# MMCHS1 register map
Vendor: Texas Instruments
Peripheral module from a debugger description file (folder omap4430).
Registers are 32-bit, access per field, reset 0x0 unless marked. A register's access mark holds for its fields unless they carry their own. Offsets are as the file gives them; lines under a group give offsets from that group; [hi:lo] are bit positions; {n}, {i} and the like mark numbered series; 'fields as' and 'values as' point back to an identical list; <NAME> marks a mode.

## MMCHS1 (part 1 of 2)
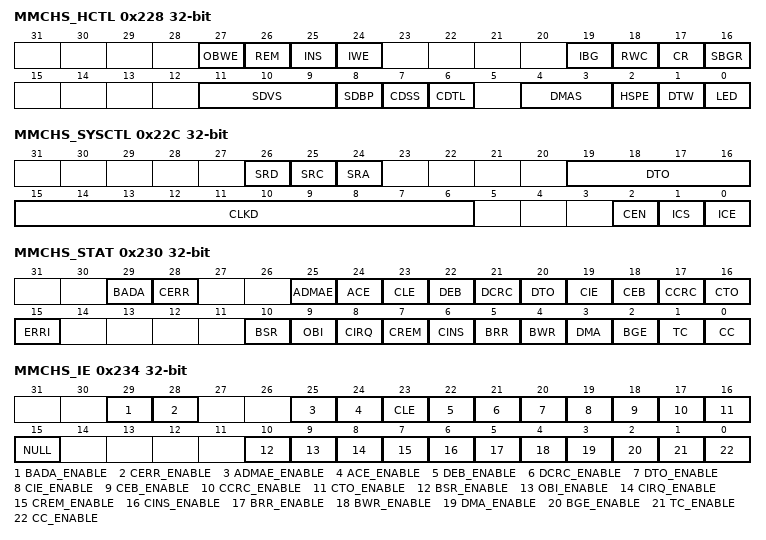
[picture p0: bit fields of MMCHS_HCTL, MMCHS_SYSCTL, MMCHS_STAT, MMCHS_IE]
0x228 MMCHS_HCTL — Control register This register defines the host controls to set power, wakeup and transfer parameters. [31:24] = Wakeup control [23:16] = Block gap control [15:8] = Power control [7:0] = Host control
  [27] OBWE rw — Wakeup event enable for 'Out-of-Band' Interrupt. This bit enables wakeup events for 'Out-of-Band' assertion. Wakeup is generated if the wakeup feature is enabled (MMCHS_SYSCONFIG[2] ENAWAKEUP). The write to this register is ignored when MMCHS_CON[14] OBIE is not set.
    0=Disable wakeup on 'Out-of-Band' Interrupt; 1=Enable wakeup on 'Out-of-Band' Interrupt
  [26] REM rw — Wakeup event enable on SD card removal This bit enables wakeup events for card removal assertion. Wakeup is generated if the wakeup feature is enabled (MMCHS_SYSCONFIG[2] ENAWAKEUP).
    0=Disable wakeup on card removal; 1=Enable wakeup on card removal
  [25] INS rw — Wakeup event enable on SD card insertion This bit enables wakeup events for card insertion assertion. Wakeup is generated if the wakeup feature is enabled (MMCHS_SYSCONFIG[2] ENAWAKEUP).
    0=Disable wakeup on card insertion; 1=Enable wakeup on card insertion
  [24] IWE rw — Wakeup event enable on SD card interrupt This bit enables wakeup events for card interrupt assertion. Wakeup is generated if the wakeup feature is enabled (MMCHS_SYSCONFIG[2] ENAWAKEUP).
    0=Disable wakeup on card interrupt; 1=Enable wakeup on card interrupt
  [19] IBG rw — Interrupt block at gap This bit is valid only in 4-bit mode of SDIO card to enable interrupt detection in the interrupt cycle at block gap for a multiple block transfer. For MMC cards and for SD card this bit should be set to 0.
    0=Disable interrupt detection at the block gap in 4-bit mode; 1=Enable interrupt detection at the block gap in 4-bit mode
  [18] RWC rw — Read wait control The read wait function is optional only for SDIO cards. If the card supports read wait, this bit must be enabled, then requesting a stop at block gap (MMCHS_HCTL[16] SBGR) generates a read wait period after the current end of block. Be careful, if read wait is not supported it may cause a conflict on DAT line.
    0=Disable Read Wait Control. Suspend/Resume cannot be supported.; 1=Enable Read Wait Control
  [17] CR rw — Continue request This bit is used to restart a transaction that was stopped by requesting a stop at block gap (MMCHS_HCTL[16] SBGR). Set this bit to 1 restarts the transfer. The bit is automatically set to 0 by the host controller when transfer has restarted i.e DAT line is active (MMCHS_PSTATE[2] DLA) or transferring data (MMCHS_PSTATE[8] WTA). The Stop at block gap request must be disabled (MMCHS_HCTL[16] SBGR = 0) before setting this bit.
    0=No affect; 1=transfer restart
  [16] SBGR rw — Stop at block gap request This bit is used to stop executing a transaction at the next block gap. The transfer can restart with a continue request (MMCHS_HCTL[17] CR) or during a suspend/resume sequence. In case of read transfer, the card must support read wait control. In case of write transfer, the host driver shall set this bit after all block data written. Until the transfer completion (MMCHS_STAT[1] TC set to 1), the host driver shall leave this bit set to 1. If this bit is set, the local host shall not write to the data register (MMCHS_DATA).
    0=Transfer mode; 1=Stop at block gap
  [11:9] SDVS rw — SD bus voltage select All cards. The host driver should set to these bits to select the voltage level for the card according to the voltage supported by the system (MMCHS_CAPA[26:24]) before starting a transfer.
    5=1.8V (Typical); 6=3.0V (Typical); 7=3.3V (Typical)
  [8] SDBP rw — SD bus power Before setting this bit, the host driver shall select the SD bus voltage (MMCHS_HCTL[11:9] SDVS). If the host controller detects the No card state, this bit is automatically set to 0. If the module is power off, a write in the command register (MMCHS_CMD) will not start the transfer. A write to this bit has no effect if the selected SD bus voltage is not supported according to capability register (MMCHS_CAPA[26:24]).
    0=Power off; 1=Power on
  [7] CDSS rw — Card Detect Signal Selection This bit selects source for the card detection.When the source for the card detection is switched, the interrupt should be disabled during the switching period by clearing the Interrupt Status/Signal Enable register in order to mask unexpected interrupt being caused by the glitch. The Interrupt Status/Signal Enable should be disabled during over the period of debouncing.
    0=SDCD# is selected (for normal use); 1=The Card Detect Test Level is selected (for test purpose)
  [6] CDTL rw — Card Detect Test Level: This bit is enabled while the Card Detect Signal Selection is set to 1 and it indicates card inserted or not.
    0=No Card; 1=Card Inserted
  [4:3] DMAS rw — DMA Select Mode: One of supported DMA modes can be selected. The host driver shall check support of DMA modes by referring the Capabilities register. Use of selected DMA is determined by DMA Enable of the Transfer Mode register. This register is only meaningful when MMCHS_HL_HWINFO[0] MADMA_EN is set to 1. When MMCHS_HL_HWINFO[0] MADMA_EN is set to 0 the bit field is read only and returned value is 0.
    2=32-bit Address ADMA2 is selected
  [2] HSPE rw — High Speed Enable: Before setting this bit, the Host Driver shall check the High Speed Support in the Capabilities register. If this bit is set to 0 (default), the Host Controller outputs CMD line and DAT lines at the falling edge of the SD Clock. If this bit is set to 1, the Host Controller outputs CMD line and DAT lines at the rising edge of the SD Clock.This bit shall not be set when dual data rate mode is activated in MMCHS_CON[19] DDR.
    0=Normal speed mode; 1=High speed mode
  [1] DTW rw — Data transfer width For MMC card, this bit must be set following a valid SWITCH command (CMD6) with the correct value and extend CSD index written in the argument. Prior to this command, the MMC card configuration register (CSD and EXT_CSD) must be verified for compliance with MMC standard specification 4.x (see section 3.6). This register has no effect when the MMC 8-bit mode is selected (register MMCHS_CON[5] DW8 set to1 ), For SD/SDIO cards, this bit must be set following a valid SET_BUS_WIDTH command (ACMD6) with the value written in bit 1 of the argument. Prior to this command, the SD card configuration register (SCR) must be verified for the supported bus width by the SD card.
    0=1-bit Data width (DAT[0] used); 1=4-bit Data width (DAT[3:0] used)
  [0] LED ro — Reserved bit. LED control feature is not supported This bit is initialized to zero, and writes to it are ignored.
0x22C MMCHS_SYSCTL — SD system control register This register defines the system controls to set software resets, clock frequency management and data timeout. [31:24] = Software resets [23:16] = Timeout control [15:0] = Clock control
  [26] SRD rw — Software reset for DAT line. This bit is set to 1 for reset and released to 0 when completed. For more information about SRD bit manipulation, see , . DAT finite state machine in both clock domain are also reset. The following registers are cleared by MMCHS_SYSCTL[26] SRD: - MMCHS_DATA - MMCHS_PSTATE[11] BRE, MMCHS_PSTATE[10] BWE, MMCHS_PSTATE[9] RTA, MMCHS_PSTATE[8] WTA, MMCHS_PSTATE[2] DLA, MMCHS_PSTATE[1] DATI - MMCHS_HCTL: SBGR and CR - MMCHS_STAT: MMCHS_STAT[5] BRR, MMCHS_STAT[4] BWR, MMCHS_STAT[2] BGE and MMCHS_STAT[1] TC Interconnect and MMC buffer data management is reinitialized.
    0=Reset completed; 1=Software reset for DAT line
  [25] SRC rw — Software reset for CMD line For more information about SRC bit manipulation, see , . This bit is set to 1 for reset and released to 0 when completed. CMD finite state-machine in both clock domain are also reset. The following registers are cleared by MMCHS_SYSCTL[25] SRC: - MMCHS_PSTATE[0] CMDI - MMCHS_STAT[0] CC Interconnect and MMC command status management is reinitialized.
    0=Reset completed; 1=Software reset for CMD line
  [24] SRA rw — Software reset for all This bit is set to 1 for reset, and released to 0 when completed. This reset affects the entire host controller except for the card detection circuit and capabilities registers.
    0=Reset completed; 1=Software reset for all the design
  [19:16] DTO rw — Data timeout counter value and busy timeout. This value determines the interval by which DAT lines timeouts are detected. The host driver needs to set this bit field based on - the maximum read access time (NAC) (Refer to the SD Specification Part1 Physical Layer), - the data read access time values (TAAC and NSAC) in the card specific data register (CSD) of the card, - the timeout clock base frequency (MMCHS_CAPA[5:0] TCF). If the card does not respond within the specified number of cycles, a data timeout error occurs (MMCHS_STAT[20] DTO). The MMCHS_SYSCTL[19:16] DTO register is also used to check busy duration, to generate busy timeout for commands with busy response or for busy programming during a write command. Timeout on CRC status is generated if no CRC token is present after a block write.
    0=TCF x 213; 1=TCF x 214; 14=TCF x 227
  [15:6] CLKD rw — Clock frequency select These bits define the ratio between MMCi_FCLK and the output clock frequency on the CLK pin of either the memory card (MMC, SD or SDIO).
    0=MMCi_FCLK bypass; 1=MMCi_FCLK bypass; 2=MMCi_FCLK / 2; 3=MMCi_FCLK / 3; 0x3FF=MMCi_FCLK / 1023
  [2] CEN rw — Clock enable This bit controls if the clock is provided to the card or not.
    0=The clock is not provided to the card . Clock frequency can be changed .; 1=The clock is provided to the card and can be automatically gated when[0] AUTOIDLE is set to 1 (default value) . The host driver shall wait to set this bit to 1 until the Internal clock is stable ([1] ICS).
  [1] ICS ro — Internal clock stable (status) This bit indicates either the internal clock is stable or not.
    0=ICS_0_r (The internal clock is not stable.); 1=ICS_1_r (The internal clock is stable after enabling the clock ([1] ICE) or after changing the clock ratio ([15:6] CLKD).)
  [0] ICE rw — Internal clock enable This register controls the internal clock activity. In very low power state, the internal clock is stopped. Note: The activity of the debounce clock (used for wakeup events) and the interface clock (used for reads and writes to the module register map) are not affected by this register.
    0=The internal clock is stopped (very low power state); 1=The internal clock oscillates and can be automatically gated when[0] AUTOIDLE is set to 1 (default value) 
0x230 MMCHS_STAT — Interrupt status register The interrupt status regroups all the status of the module internal events that can generate an interrupt. [31:16] = Error Interrupt Status [15:0] = Normal Interrupt Status
  [29] BADA rw — Bad access to data space This bit is set automatically to indicate a bad access to buffer when not allowed: -This bit is set during a read access to the data register (MMCHS_DATA) while buffer reads are not allowed (MMCHS_PSTATE[11] BRE = 0) -This bit is set during a write access to the data register (MMCHS_DATA) while buffer writes are not allowed (MMCHS_PSTATE[10] BWE = 0)
    0=BADA_0_w (Status bit unchanged); 0=BADA_0_r (No Interrupt.); 1=BADA_1_r (Bad Access); 1=BADA_1_w (Status is cleared)
  [28] CERR rw — Card error This bit is set automatically when there is at least one error in a response of type R1, R1b, R6, R5 or R5b. Only bits referenced as type E(error) in status field in the response can set a card status error. An error bit in the response is flagged only if corresponding bit in card status response error MMCHS_CSRE in set. There is no card error detection for autoCMD12 command. The host driver shall read MMCHS_RSP76 register to detect error bits in the command response.
    0=CERR_0_w (Status bit unchanged); 0=CERR_0_r (No Error); 1=CERR_1_w (Status is cleared); 1=CERR_1_r (Card error)
  [25] ADMAE rw — ADMA Error: This bit is set when the Host Controller detects errors during ADMA based data transfer. The state of the ADMA at an error occurrence is saved in the ADMA Error Status Register.In addition, the Host Controller generates this interrupt when it detects invalid descriptor data (Valid=0) at the ST_FDS state. ADMA Error State in the ADMA Error Status indicates that an error occurs in ST_FDS state. The Host Driver may find that Valid bit is not set at the error descriptor.
    0=ADMAE_0_w (Status bit unchanged); 0=ADMAE_0_r (No Interrupt.); 1=ADMAE_1_w (Status is cleared); 1=ADMAE_1_r (ADMA error)
  [24] ACE rw — Auto CMD12 error This bit is set automatically when one of the bits in Auto CMD12 Error status register has changed from 0 to 1.
    0=ACE_0_w (Status bit unchanged); 0=ACE_0_r (No Error.); 1=ACE_1_r (AutoCMD12 error); 1=ACE_1_w (Status is cleared)
  [23] CLE ro — Reserved. Current limit error is not supported. These bits are initialized to zero, and writes to them are ignored.
  [22] DEB rw — Data End Bit error This bit is set automatically when detecting a 0 at the end bit position of read data on DAT line or at the end position of the CRC status in write mode.
    0=DEB_0_r (No Error); 0=DEB_0_w (Status bit unchanged); 1=DEB_1_w (Status is cleared); 1=DEB_1_r (Data end bit error)
  [21] DCRC rw — Data CRC Error This bit is set automatically when there is a CRC16 error in the data phase response following a block read command or if there is a 3-bit CRC status different of a position '010' token during a block write command.
    0=DCRC_0_r (No Error.); 0=DCRC_0_w (Status bit unchanged); 1=DCRC_1_r (Data CRC error); 1=DCRC_1_w (Status is cleared)
  [20] DTO rw — Data timeout error This bit is set automatically according to the following conditions: - busy timeout for R1b, R5b response type - busy timeout after write CRC status - write CRC status timeout - read data timeout
    0=DTO_0_r (No error.); 0=DTO_0_w (Status bit unchanged); 1=DTO_1_w (Status is cleared); 1=DTO_1_r (Time out)
  [19] CIE rw — Command index error This bit is set automatically when response index differs from corresponding command index previously emitted. It depends on the enable in MMCHS_CMD[20] CICE register.
    0=CIE_0_r (No error.); 0=CIE_0_w (Status bit unchanged); 1=CIE_1_r (Command index error); 1=CIE_1_w (Status is cleared)
  [18] CEB rw — Command end bit error This bit is set automatically when detecting a 0 at the end bit position of a command response.
    0=CEB_0_w (Status bit unchanged); 0=CEB_0_r (No error.); 1=CEB_1_r (Command end bit error); 1=CEB_1_w (Status is cleared)
  [17] CCRC rw — Command CRC Error This bit is set automatically when there is a CRC7 error in the command response depending on the enable in MMCHS_CMD[19] CCCE register.
    0=CCRC_0_r (No Error.); 0=CCRC_0_w (Status bit unchanged); 1=CCRC_1_w (Status is cleared); 1=CCRC_1_r (Command CRC error)
  [16] CTO rw — Command Timeout Error This bit is set automatically when no response is received within 64 clock cycles from the end bit of the command. For commands that reply within 5 clock cycles - the timeout is still detected at 64 clock cycles.
    0=CTO_0_w (Status bit unchanged); 0=CTO_0_r (No error); 1=CTO_1_r (Time Out); 1=CTO_1_w (Status is cleared)
  [15] ERRI ro — Error Interrupt If any of the bits in the Error Interrupt Status register (MMCHS_STAT[24:15]) are set, then this bit is set to 1. Therefore the host driver can efficiently test for an error by checking this bit first. Writes to this bit are ignored.
    0=ERRI_0_r (No Interrupt.); 1=ERRI_1_r (Error interrupt event(s) occurred)
  [10] BSR rw — Boot status received interrupt This bit is set automatically when MMCHS_CON[18] BOOT_CF0 is set 0x0 or 0x1 and a boot status is received on DAT[0] line. This interrupt is only useful for MMC card.
    0=BSR_0_w (Status bit unchanged); 0=BSR_0_r (No Interrupt.); 1=BSR_1_w (Status is cleared); 1=BSR_1_r (Boot status received interrupt.)
  [9] OBI rw — Out-Of-Band interrupt This bit is set automatically when MMCHS_CON[14] OBIE is set and an Out-of-Band interrupt occurs on OBI pin. The interrupt detection depends on polarity controlled by MMCHS_CON[13] OBIP. This interrupt is only useful for MMC card. The Out-of-Band interrupt signal is a system specific feature for future use, this signal is not required for existing specification implementation.
    0=OBI_0_r (No Out-Of-Band interrupt.); 0=OBI_0_w (Status bit unchanged); 1=OBI_1_r (Interrupt Out-Of-Band occurs); 1=OBI_1_w (Status is cleared)
  [8] CIRQ ro — Card interrupt This bit is only used for SD and SDIO and CE-ATA cards. In 1-bit mode, interrupt source is asynchronous (can be a source of asynchronous wakeup). In 4-bit mode, interrupt source is sampled during the interrupt cycle. In CE-ATA mode, interrupt source is detected when the card drives CMD line to zero during one cycle after data transmission end.All modes above are fully exclusive. The controller interrupt must be clear by setting MMCHS_IE[8] CIRQ_ENABLE to 0, then the host driver must start the interrupt service with card (clearing card interrupt status) to remove card interrupt source. Otherwise the Controller interrupt will be reasserted as soon as MMCHS_IE[8] CIRQ_ENABLE is set to 1. Writes to this bit are ignored.
    0=CIRQ_0_r (No card interrupt); 1=CIRQ_1_r (Generate card interrupt)
  [7] CREM rw — Card removal This bit is set automatically when MMCHS_PSTATE[16] CINS changes from 1 to 0. A clear of this bit doesn't affect Card inserted present state (MMCHS_PSTATE[16] CINS).
    0=CREM_0_w (Status bit unchanged); 0=CREM_0_r (Card state stable or Debouncing); 1=CREM_1_r (Card removed); 1=CREM_1_w (Status is cleared)
  [6] CINS rw — Card insertion This bit is set automatically when MMCHS_PSTATE[16] changes from 0 to 1. A clear of this bit doesn't affect Card inserted present state (MMCHS_PSTATE[16] CINS).
    0=CINS_0_r (Card state stable or debouncing); 0=CINS_0_w (Status bit unchanged); 1=CINS_1_w (Status is cleared); 1=CINS_1_r (Card inserted)
  [5] BRR rw — Buffer read ready This bit is set automatically during a read operation to the card (see class 2 - block oriented read commands) when one block specified by MMCHS_BLK[11:0] BLEN is completely written in the buffer. It indicates that the memory card has filled out the buffer and that the local host needs to empty the buffer by reading it. Note: If the DMA receive-mode is enabled, this bit is never set; instead a DMA receive request to the main DMA controller of the system is generated.
    0=BRR_0_r (Not Ready to read buffer); 0=BRR_0_w (Status bit unchanged); 1=BRR_1_r (Ready to read buffer); 1=BRR_1_w (Status is cleared)
  [4] BWR rw — Buffer write ready This bit is set automatically during a write operation to the card (see class 4 - block oriented write command) when the host can write a complete block as specified by MMCHS_BLK[11:0] BLEN. It indicates that the memory card has emptied one block from the buffer and that the local host is able to write one block of data into the buffer. Note: If the DMA transmit mode is enabled, this bit is never set; instead, a DMA transmit request to the main DMA controller of the system is generated.
    0=BWR_0_w (Status bit unchanged); 0=BWR_0_r (Not Ready to write buffer); 1=BWR_1_r (Ready to write buffer); 1=BWR_1_w (Status is cleared)
  [3] DMA rw — DMA interrupt : This status is set when an interrupt is required in the ADMA instruction and after the data transfer completion.
    0=DMA_0_r (Dma interrupt detected); 0=DMA_0_w (Status bit unchanged); 1=DMA_1_w (Status is cleared); 1=DMA_1_r (No dma interrupt)
  [2] BGE rw — Block gap event When a stop at block gap is requested (MMCHS_HCTL[16] SBGR), this bit is automatically set when transaction is stopped at the block gap during a read or write operation. This event does not occur when the stop at block gap is requested on the last block. In read mode, a 1-to-0 transition of the DAT Line active status (MMCHS_PSTATE[2] DLA) between data blocks generates a Block gap event interrupt.
    0=BGE_0_r (No block gap event); 0=BGE_0_w (Status bit unchanged); 1=BGE_1_w (Status is cleared); 1=BGE_1_r (Transaction stopped at block gap)
  [1] TC rw — Transfer completed This bit is always set when a read/write transfer is completed or between two blocks when the transfer is stopped due to a stop at block gap request (MMCHS_HCTL[16] SBGR). In Read mode: This bit is automatically set on completion of a read transfer (MMCHS_PSTATE[9] RTA). In write mode: This bit is set automatically on completion of the DAT line use (MMCHS_PSTATE[2] DLA).
    0=TC_0_w (Status bit unchanged); 0=TC_0_r (No transfer complete); 1=TC_1_w (Status is cleared); 1=TC_1_r (Data transfer complete)
  [0] CC rw — Command complete This bit is set when a 1-to-0 transition occurs in the register command inhibit (MMCHS_PSTATE[0] CMDI) If the command is a type for which no response is expected, then the command complete interrupt is generated at the end of the command. A command timeout error (MMCHS_STAT[16] CTO) has higher priority than command complete (MMCHS_STAT[0] CC). If a response is expected but none is received, then a command timeout error is detected and signaled instead of the command complete interrupt.
    0=CC_0_w (Status bit unchanged); 0=CC_0_r (No Command complete); 1=CC_1_w (Status is cleared); 1=CC_1_r (Command complete)
0x234 MMCHS_IE — Interrupt SD enable register This register allows to enable/disable the module to set status bits, on an event-by-event basis. [31:16] = Error Interrupt Status Enable [15:0] = Normal Interrupt Status Enable
  [29] BADA_ENABLE rw — Bad access to data space Interrupt Enable
    0=Masked; 1=Enabled
  [28] CERR_ENABLE rw — Card error interrupt Enable
    0=Masked; 1=Enabled
  [25] ADMAE_ENABLE rw — ADMA error Interrupt Enable
    0=Masked; 1=Enabled
  [24] ACE_ENABLE rw — Auto CMD12 error Interrupt Enable
    0=Masked; 1=Enabled
  [23] CLE ro — Reserved bit. Current limit error is not supported. These bits are initialized to zero, and writes to them are ignored.
  [22] DEB_ENABLE rw — Data end bit error Interrupt Enable
    0=Masked; 1=Enabled
  [21] DCRC_ENABLE rw — Data CRC error Interrupt Enable
    0=Masked; 1=Enabled
  [20] DTO_ENABLE rw — Data timeout error Interrupt Enable
    0=The data timeout detection is deactivated. The host controller provides the clock to the card until the card sends the data or the transfer is aborted.; 1=The data timeout detection is enabled
  [19] CIE_ENABLE rw — Command index error Interrupt Enable
    0=Masked; 1=Enabled
  [18] CEB_ENABLE rw — Command end bit error Interrupt Enable
    0=Masked; 1=Enabled
  [17] CCRC_ENABLE rw — Command CRC error Interrupt Enable
    0=Masked; 1=Enabled
  [16] CTO_ENABLE rw — Command timeout error Interrupt Enable
    0=Masked; 1=Enabled
  [15] NULL ro — Fixed to 0 The host driver shall control error interrupts using the Error Interrupt Signal Enable register. Writes to this bit are ignored
  [10] BSR_ENABLE rw — Boot status interrupt Enable A write to this register when MMCHS_CON[17] BOOT_ACK is set to 0x0 is ignored.
    0=Masked; 1=Enabled
  [9] OBI_ENABLE rw — Out-of-Band interrupt Enable A write to this register when MMCHS_CON[14] OBIE is set to 0 is ignored.
    0=Masked; 1=Enabled
  [8] CIRQ_ENABLE rw — Card interrupt Enable A clear of this bit also clears the corresponding status bit. During 1-bit mode, if the interrupt routine doesn't remove the source of a card interrupt in the SDIO card, the status bit is reasserted when this bit is set to 1.
    0=Masked; 1=Enabled
  [7] CREM_ENABLE rw — Card removal Interrupt Enable
    0=Masked; 1=Enabled
  [6] CINS_ENABLE rw — Card insertion Interrupt Enable
    0=Masked; 1=Enabled
  [5] BRR_ENABLE rw — Buffer Read Ready Interrupt Enable
    0=Masked; 1=Enabled
  [4] BWR_ENABLE rw — Buffer Write Ready Interrupt Enable
    0=Masked; 1=Enabled
  [3] DMA_ENABLE rw — DMA interrupt Enable
    0=Masked; 1=Enabled
  [2] BGE_ENABLE rw — Block Gap Event Interrupt Enable
    0=Masked; 1=Enabled
  [1] TC_ENABLE rw — Transfer completed Interrupt Enable
    0=Masked; 1=Enabled
  [0] CC_ENABLE rw — Command completed Interrupt Enable
    0=Masked; 1=Enabled
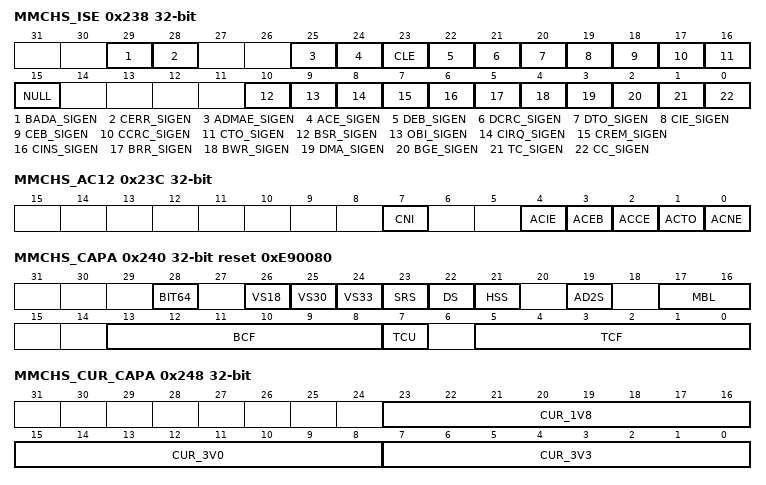
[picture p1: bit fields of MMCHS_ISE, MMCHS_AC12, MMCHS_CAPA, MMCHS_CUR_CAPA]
0x238 MMCHS_ISE — Interrupt signal enable register This register allows to enable/disable the module internal sources of status, on an event-by-event basis. [31:16] = Error Interrupt Signal Enable [15:0] = Normal Interrupt Signal Enable
  [29] BADA_SIGEN rw — Bad access to data space signal status Enable
    0=Masked; 1=Enabled
  [28] CERR_SIGEN rw — Card error interrupt signal status Enable
    0=Masked; 1=Enabled
  [25] ADMAE_SIGEN rw — ADMA error signal status Enable
    0=Masked; 1=Enabled
  [24] ACE_SIGEN rw — Auto CMD12 error signal status Enable
    0=Masked; 1=Enabled
  [23] CLE ro — Reserved bit. Current limit error is not supported. These bits are initialized to zero, and writes to them are ignored.
  [22] DEB_SIGEN rw — Data end bit error signal status Enable
    0=Masked; 1=Enabled
  [21] DCRC_SIGEN rw — Data CRC error signal status Enable
    0=Masked; 1=Enabled
  [20] DTO_SIGEN rw — Data timeout error signal status Enable
    0=Masked; 1=Enabled
  [19] CIE_SIGEN rw — Command index error signal status Enable
    0=Masked; 1=Enabled
  [18] CEB_SIGEN rw — Command end bit error signal status Enable
    0=Masked; 1=Enabled
  [17] CCRC_SIGEN rw — Command CRC error signal status Enable
    0=Masked; 1=Enabled
  [16] CTO_SIGEN rw — Command timeout error signal status Enable
    0=Masked; 1=Enabled
  [15] NULL ro — Fixed to 0 The host driver shall control error interrupts using the Error Interrupt Signal Enable register. Writes to this bit are ignored
  [10] BSR_SIGEN rw — Boot status signal status EnableA write to this register whenMMCHS_CON[17] BOOT_ACK is set to 0x0 is ignored.
    0=Masked; 1=Enabled
  [9] OBI_SIGEN rw — Out-Of-Band Interrupt signal status Enable A write to this register when MMCHS_CON[14] OBIE is set to 0 is ignored.
    0=Masked; 1=Enabled
  [8] CIRQ_SIGEN rw — Card interrupt signal status Enable
    0=Masked; 1=Enabled
  [7] CREM_SIGEN rw — Card removal signal status Enable
    0=Masked; 1=Enabled
  [6] CINS_SIGEN rw — Card insertion signal status Enable
    0=Masked; 1=Enabled
  [5] BRR_SIGEN rw — Buffer Read Ready signal status Enable
    0=Masked; 1=Enabled
  [4] BWR_SIGEN rw — Buffer Write Ready signal status Enable
    0=Masked; 1=Enabled
  [3] DMA_SIGEN rw — DMA interrupt Signal status enable
    0=Masked; 1=Enabled
  [2] BGE_SIGEN rw — Black Gap Event signal status Enable
    0=Masked; 1=Enabled
  [1] TC_SIGEN rw — Transfer completed signal status Enable
    0=Masked; 1=Enabled
  [0] CC_SIGEN rw — Command completed signal status Enable
    0=Masked; 1=Enabled
0x23C MMCHS_AC12 ro — Auto CMD12 Error Status Register The host driver may determine which of the errors cases related to Auto CMD12 has occurred by checking this register when an Auto CMD12 Error interrupt occurs. This register is valid only when Auto CMD12 is enabled ([2] ACEN) and Auto CMD12Error ([24] ACE) is set to 1. Note: These bits are automatically reset when starting a new adtc command with data.
  [7] CNI — Command not issue by Auto CMD12 error If this bit is set to 1, it means that pending command is not executed due to Auto CMD12 error : ACEB, ACCE, ACTO or ACNE.
    0=CNI_0_r (Not error); 1=CNI_1_r (Command not issued)
  [4] ACIE — Auto CMD12 index error This bit is a set to 1 when response index differs from corresponding command auto CMD12 index previously emitted. This bit depends on the command index check enable (MMCHS_CMD[20] CICE).
    0=ACIE_0_r (No error); 1=ACIE_1_r (Auto CMD12 Index Error)
  [3] ACEB — Auto CMD12 end bit error This bit is set to 1 when detecting a 0 at the end bit position of auto CMD12 command response.
    0=ACEB_0_r (No error); 1=ACEB_1_r (AutoCMD12 End bit Error)
  [2] ACCE — Auto CMD12 CRC error This bit is automatically set to 1 when a CRC7 error is detected in the auto CMD12 command response depending on the enable in MMCHS_CMD[19] CCCE register.
    0=ACCE_0_r (No error); 1=ACCE_1_r (Auto CMD12 CRC Error)
  [1] ACTO — Auto CMD12 timeout error This bit is set to 1 if no response is received within 64 clock cycles from the end bit of the auto CMD12 command.
    0=ACTO_0_r (No error); 1=ACTO_1_r (Auto CMD12 Time Out)
  [0] ACNE — Auto CMD12 not executed This bit is set to 1 if multiple block data transfer command has started and if an error occurs in command before Auto CMD12 starts.
    0=ACNE_0_r (Auto CMD12 Executed); 1=ACNE_1_r (Auto CMD12 Not Executed)
0x240 MMCHS_CAPA reset 0xE90080 — Capabilities register This register lists the capabilities of the MMC/SD/SDIO host controller.
  [28] BIT64 ro — 64-bit system bus support: Setting 1 to this bit indicates that the Host Controller supports 64-bit address descriptor mode and is connected to 64-bit address system bus.
    0=BIT64_0_r (32-bit system bus address); 1=BIT64_1_r (64-bit system bus address)
  [26] VS18 rw — Voltage support 1.8 V Initialization of this register (via a write access to this register) depends on the system capabilities. The host driver shall not modify this register after the initilaization. This register is only reinitialized by a hard reset (via RESETN signal)
    0=VS18_0_w (1.8 V not supported); 0=VS18_0_r (1.8 V not supported); 1=VS18_1_r (1.8 V supported); 1=VS18_1_w (1.8 V supported)
  [25] VS30 rw — Voltage support 3.0 V Initialization of this register (via a write access to this register) depends on the system capabilities. The host driver shall not modify this register after the initilaization. This register is only reinitialized by a hard reset (via RESETN signal)
    0=VS30_0_r (3.0 V not supported); 0=VS30_0_w (3.0 V not supported); 1=VS30_1_w (3.0 V supported); 1=VS30_1_r (3.0 V supported)
  [24] VS33 rw — Voltage support 3.3 V Initialization of this register (via a write access to this register) depends on the system capabilities. The host driver shall not modify this register after the initilaization. This register is only reinitialized by a hard reset (via RESETN signal)
    0=VS33_0_r (3.3 V not supported); 0=VS33_0_w (3.3 V not supported); 1=VS33_1_w (3.3 V supported); 1=VS33_1_r (3.3 V supported)
  [23] SRS ro — Suspend/Resume support (SDIO cards only) This bit indicates whether the host controller supports suspend/resume functionality.
    0=SRS_0_r (The host controller does not suspend/resume functionality.); 1=SRS_1_r (The host controller supports suspend/resume functionality.)
  [22] DS ro — DMA support This bit indicates that the Host Controller is able to use DMA to transfer data between system memory and the Host Controller directly.
    0=DS_0_r (DMA not supported); 1=DS_1_r (DMA supported)
  [21] HSS ro — High-speed support This bit indicates that the host controller supports high-speed operations and can supply an up-to maximum card frequency.
    0=HSS_0_r (High speed not supported); 1=HSS_1_r (High speed supported)
  [19] AD2S ro — ADMA2 support: This bit indicates whether the host controller is capable of using ADMA2. It depends on setting of generic parameter MMCHS_HL_HWINFO[0] MADMA_EN
    0=AD2S_0_r (ADMA2 not supported); 1=AD2S_1_r (ADMA2 supported)
  [17:16] MBL ro — Maximum block length This value indicates the maximum block size that the host driver can read and write to the buffer in the host controller. This value depends on definition of generic parameter with a max value of 2048 bytes. The host controller supports 512- byte and 1024-byte block transfers.
    0=MBL_0_r (512 bytes); 1=MBL_1_r (1024 bytes); 2=MBL_2_r (2048 bytes)
  [13:8] BCF ro — Base clock frequency for clock provided to the card.
    0=BCF_0_r (The value indicating the base (maximum) frequency for the output clock provided to the card is system dependent and is not available in this register. Get the information via another method.)
  [7] TCU ro — Timeout clock unit This bit shows the unit of base clock frequency used to detect Data Timeout Error (MMCHS_STAT[20] DTO).
    0=TCU_0_r (kHz); 1=TCU_1_r (MHz)
  [5:0] TCF ro — Timeout clock frequency The timeout clock frequency is used to detect Data Timeout Error (MMCHS_STAT[20] DTO).
    0=TCF_0_r (The timeout clock frequency depends on the frequency of the clock provided to the card. The value of the timeout clock frequency is not available in this register.)
0x248 MMCHS_CUR_CAPA — Maximum current capabilities Register This register indicates the maximum current capability for each voltage. The value is meaningful if the voltage support is set in the capabilities register (). Initialization of this register (via a write access to this register) depends on the system capabilities. The host driver shall not modify this register after the initilaization. This register is only reinitialized by a hard reset (via RESETN signal)
  [23:16] CUR_1V8 rw — Maximum current for 1.8V
    0=CUR_1V8_0_r (The maximum current capability for this voltage is not available. Feature not implemented.)
  [15:8] CUR_3V0 rw — Maximum current for 3.0V
    0=CUR_3V0_0_r (The maximum current capability for this voltage is not available. Feature not implemented.)
  [7:0] CUR_3V3 rw — Maximum current for 3.3V
    0=CUR_3V3_0_r (The maximum current capability for this voltage is not available. Feature not implemented.)
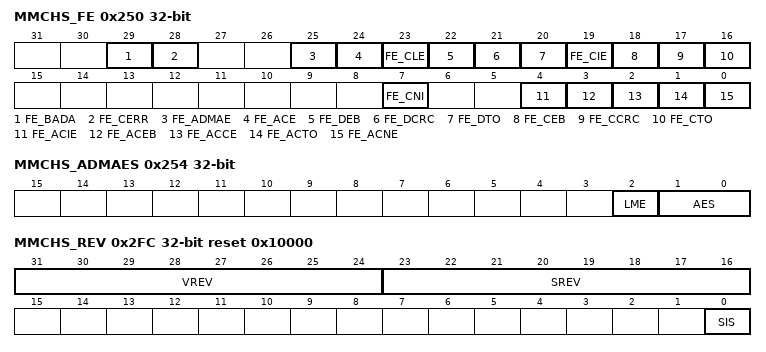
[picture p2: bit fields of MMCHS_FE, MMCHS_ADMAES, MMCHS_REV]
0x250 MMCHS_FE access not given — Force Event Register for Error Interrupt status The force Event Register is not a physically implemented register. Rather, it is an address at which the Error Interrupt Status register can be written. The effect of a write to this address will be reflected in the Error Interrupt Status Register, if corresponding bit of the Error Interrupt Status Enable Register is set.
  [29] FE_BADA wo — Force Event Bad access to data space
    0=FE_BADA_0_w (No effect, No Interrupt.); 1=FE_BADA_1_w (Interrupt Forced)
  [28] FE_CERR wo — Force Event Card error
    0=FE_CERR_0_w (No effect, No Interrupt.); 1=FE_CERR_1_w (Interrupt Forced)
  [25] FE_ADMAE wo — Force Event ADMA Error:
    0=FE_ADMAE_0_w (No effect, No Interrupt.); 1=FE_ADMAE_1_w (Interrupt Forced)
  [24] FE_ACE wo — Force Event Auto CMD12 error
    0=FE_ACE_0_w (No effect, No Interrupt.); 1=FE_ACE_1_w (Interrupt Forced)
  [23] FE_CLE — Reserved. Current limit error is not supported. These bits are initialized to zero, and writes to them are ignored. (access N/A)
  [22] FE_DEB wo — Force Event Data End Bit error
    0=FE_DEB_0_w (No effect, No Interrupt.); 1=FE_DEB_1_w (Interrupt Forced)
  [21] FE_DCRC wo — Force Event Data CRC Error
    0=FE_DCRC_0_w (No effect, No Interrupt.); 1=FE_DCRC_1_w (Interrupt Forced)
  [20] FE_DTO wo — Force Event Data timeout error
    0=FE_DTO_0_w (No effect, No Interrupt.); 1=FE_DTO_1_w (Interrupt Forced)
  [19] FE_CIE wo — Force Event Command index error
    0=FE_CIE_0_w (No effect, No Interrupt.); 1=FE_CIE_1_w (Interrupt Forced)
  [18] FE_CEB wo — Force Event Command end bit error
    0=FE_CEB_0_w (No effect, No Interrupt.); 1=FE_CEB_1_w (Interrupt Forced)
  [17] FE_CCRC wo — Force Event Command CRC Error
    0=FE_CCRC_0_w (No effect, No Interrupt.); 1=FE_CCRC_1_w (Interrupt Forced)
  [16] FE_CTO wo — Command Timeout ErrorThis bit is set automatically when no response is received within 64 clock cycles from the end bit of the command. . For commands that reply within 5 clock cycles - the timeout is still detected at 64 clock cycles. .
    0=FE_CTO_0_w (Status bit unchanged); 1=FE_CTO_1_w (Status is cleared)
  [7] FE_CNI wo — Force Event Command not issue by Auto CMD12 error
    0=FE_CNI_0_w (No effect, No Interrupt.); 1=FE_CNI_1_w (Interrupt Forced)
  [4] FE_ACIE wo — Force Event Auto CMD12 index error
    0=FE_ACIE_0_w (No effect, No Interrupt.); 1=FE_ACIE_1_w (Interrupt Forced)
  [3] FE_ACEB wo — Force Event Auto CMD12 end bit error
    0=FE_ACEB_0_w (No effect, No Interrupt.); 1=FE_ACEB_1_w (Interrupt Forced)
  [2] FE_ACCE wo — Force Event Auto CMD12 CRC error
    0=FE_ACCE_0_w (No effect, No Interrupt.); 1=FE_ACCE_1_w (Interrupt Forced)
  [1] FE_ACTO wo — Force Event Auto CMD12 timeout error
    0=FE_ACTO_0_w (No effect, No Interrupt.); 1=FE_ACTO_1_w (Interrupt Forced)
  [0] FE_ACNE wo — Force Event Auto CMD12 not executed
    0=FE_ACNE_0_w (No effect, No Interrupt.); 1=FE_ACNE_1_w (Interrupt Forced)
0x254 MMCHS_ADMAES — ADMA Error Status Register When ADMA Error Interrupt is occurred, the ADMA Error States field in this register holds the ADMA state and the ADMA System Address Register holds the address around the error descriptor. For recovering the error, the Host Driver requires the ADMA state to identify the error descriptor address as follows: ST_STOP: Previous location set in the ADMA System Address register is the error descriptor address ST_FDS: Current location set in the ADMA System Address register is the error descriptor address ST_CADR: This sate is never set because do not generate ADMA error in this state. ST_TFR: Previous location set in the ADMA System Address register is the error descriptor address In case of write operation, the Host Driver should use ACMD22 to get the number of written block rather than using this information, since unwritten data may exist in the Host Controller. The Host Controller generates the ADMA Error Interrupt when it detects invalid descriptor data (Valid=0) at the ST_FDS state. In this case, ADMA Error State indicates that an error occurs at ST_FDS state. The Host Driver may find that the Valid bit is not set in the error descriptor.
  [2] LME rw — ADMA Length Mismatch Error: (1) While Block Count Enable being set, the total data length specified by the Descriptor table is different from that specified by the Block Count and Block Length. (2) Total data length can not be divided by the block length.
    0=No Error; 1=Error
  [1:0] AES rw — ADMA Error State his field indicates the state of ADMA when error is occurred during ADMA data transfer. This field never indicates '10' because ADMA never stops in this state.
    0=ST_STOP (Stop DMA)Contents of SYS_SDR register; 1=ST_STOP (Stop DMA)Points the error descriptor; 2=Never set this state(Not used); 3=ST_TFR (Transfer Data)Points the next of the error descriptor
0x258 MMCHS_ADMASAL rw — ADMA System address Low bits
  [31:0] ADMA_A32B — ADMA System address 32 bits.This register holds byte address of executing command of the Descriptor table. 32-bit Address Descriptor uses lower 32-bit of this register. At the start of ADMA, the Host Driver shall set start address of the Descriptor table. The ADMA increments this register address, which points to next line, when every fetching a Descriptor line. When the ADMA Error Interrupt is generated, this register shall hold valid Descriptor address depending on the ADMA state. The Host Driver shall program Descriptor Table on 32-bit boundary and set 32-bit boundary address to this register. ADMA2 ignores lower 2-bit of this register and assumes it to be 00b.
0x2FC MMCHS_REV ro reset 0x10000 (reset mask 0xFFFFFF) — Versions Register This register contains the hard coded RTL vendor revision number, the version number of SD specification compliancy and a slot status bit. [31:16] = Host controller version [15:0] = Slot Interrupt Status
  [31:24] VREV — Vendor Version Number: IP revision [7:4] Major revision [3:0] Minor revision Examples: 0x10 for 1.0 0x21 for 2.1
  [23:16] SREV — Specification Version Number This status indicates the Standard SD Host Controller Specification Version. The upper and lower 4-bits indicate the version.
    0=SREV_0_r (SD Host Specification Version 1.0); 1=SREV_1_r (SD Host Specification Version 2.0)
  [0] SIS — Slot Interrupt Status This status bit indicates the inverted state of interrupt signal for the module. By a power on reset or by setting a software reset for all (MMCHS_SYSCTL[24] SRA), the interrupt signal shall be de-asserted and this status shall read 0.
